# AT90PWM1 register map
Vendor: Atmel; File version: 1.0
CPU: other r0p0, little endian, no MPU, no FPU, 4 interrupt priority bits
Registers are 8-bit, read-write, reset 0x0 unless marked. A register's access mark holds for its fields unless they carry their own. Offsets are from the block's base; [hi:lo] are bit positions; {n}, {i} and the like mark numbered series; 'fields as' and 'values as' point back to an identical list.

## PSC2 — Power Stage Controller
Base 0x000000A4
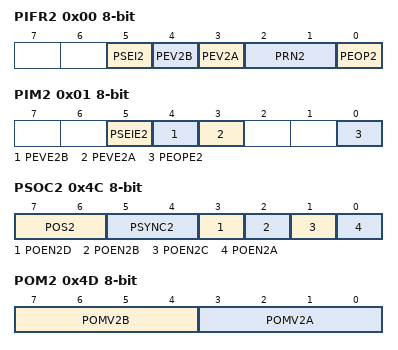
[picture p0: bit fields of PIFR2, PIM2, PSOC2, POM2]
0x00 PIFR2 — PSC2 Interrupt Flag Register
  [5] PSEI2 — PSC 2 Synchro Error Interrupt
  [4] PEV2B — External Event B Interrupt
  [3] PEV2A — External Event A Interrupt
  [2:1] PRN2 — Ramp Number
    {v}={v+1} (v=0..3)
  [0] PEOP2 — End of PSC2 Interrupt
0x01 PIM2 — PSC2 Interrupt Mask Register
  [5] PSEIE2 — PSC 2 Synchro Error Interrupt Enable
  [4] PEVE2B — External Event B Interrupt Enable
  [3] PEVE2A — External Event A Interrupt Enable
  [0] PEOPE2 — End of Cycle Interrupt Enable
0x4C PSOC2 — PSC2 Synchro and Output Configuration
  [7:6] POS2 — PSC 2 Output 23 Select
  [5:4] PSYNC2 — Synchronization Out for ADC Selection
  [3] POEN2D — PSCOUT23 Output Enable
  [2] POEN2B — PSCOUT21 Output Enable
  [1] POEN2C — PSCOUT22 Output Enable
  [0] POEN2A — PSCOUT20 Output Enable
0x4D POM2 — PSC 2 Output Matrix
  [7:4] POMV2B — Output Matrix Output B Ramps
  [3:0] POMV2A — Output Matrix Output A Ramps
0x4E OCR2SA 16-bit (reset mask 0xFF) — Output Compare SA Register
0x50 OCR2RA 16-bit (reset mask 0xFF) — Output Compare RA Register
0x52 OCR2SB 16-bit (reset mask 0xFF) — Output Compare SB Register
0x54 OCR2RB 16-bit (reset mask 0xFF) — Output Compare RB Register
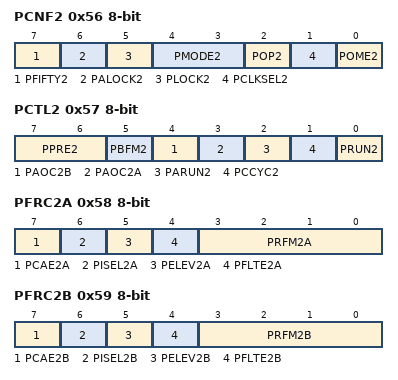
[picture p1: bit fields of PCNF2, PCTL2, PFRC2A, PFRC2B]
0x56 PCNF2 — PSC 2 Configuration Register
  [7] PFIFTY2 — PSC 2 Fifty
  [6] PALOCK2 — PSC 2 Autolock
  [5] PLOCK2 — PSC 2 Lock
  [4:3] PMODE2 — PSC 2 Mode
    0=One Ramp Mode; 1=Two Ramp Mode; 2=Four Ramp Mode; 3=Center Aligned Mode
  [2] POP2 — PSC 2 Output Polarity
  [1] PCLKSEL2 — PSC 2 Input Clock Select
  [0] POME2 — PSC 2 Output Matrix Enable
0x57 PCTL2 — PSC 2 Control Register
  [7:6] PPRE2 — PSC 2 Prescaler Selects
    0=No divider on PSC input clock; 1=Divide the PSC input clock by 4; 2=Divide the PSC input clock by 16; 3=Divide the PSC input clock by 64
  [5] PBFM2 — Balance Flank Width Modulation
  [4] PAOC2B — PSC 2 Asynchronous Output Control B
  [3] PAOC2A — PSC 2 Asynchronous Output Control A
  [2] PARUN2 — PSC2 Auto Run
  [1] PCCYC2 — PSC2 Complete Cycle
  [0] PRUN2 — PSC 2 Run
0x58 PFRC2A — PSC 2 Input B Control
  [7] PCAE2A — PSC 2 Capture Enable Input Part A
  [6] PISEL2A — PSC 2 Input Select for Part A
  [5] PELEV2A — PSC 2 Edge Level Selector on Input Part A
  [4] PFLTE2A — PSC 2 Filter Enable on Input Part A
  [3:0] PRFM2A — PSC 2 Retrigger and Fault Mode for Part A
    0=No action, PSC Input is ignored; 1=Stop signal, Jump to Opposite Dead-Time and Wait; 2=Stop signal, Execute Opposite Dead-Time and Wait; 3=Stop signal, Execute Opposite while Fault active; 4=Deactivate outputs without changing timing; 5=Stop signal and Insert Dead-Time; 6=Stop signal, Jump to Opposite Dead-Time and Wait; 7=Halt PSC and Wait for Software Action; 8=Edge Retrigger PSC; 9=Fixed Frequency Edge Retrigger PSC; 14=Fixed Frequency Edge Retrigger PSC and Disactivate Output
0x59 PFRC2B — PSC 2 Input B Control
  [7] PCAE2B — PSC 2 Capture Enable Input Part B
  [6] PISEL2B — PSC 2 Input Select for Part B
  [5] PELEV2B — PSC 2 Edge Level Selector on Input Part B
  [4] PFLTE2B — PSC 2 Filter Enable on Input Part B
  [3:0] PRFM2B — PSC 2 Retrigger and Fault Mode for Part B
    values as PFRC2A.PRFM2A
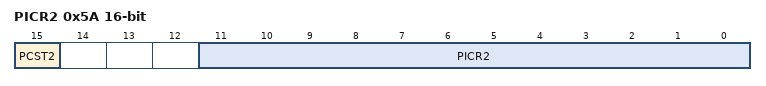
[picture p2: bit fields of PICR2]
0x5A PICR2 16-bit (reset mask 0xFF) — PSC 2 Input Capture Register
  [15] PCST2 — PSC 2 Capture Software Trig bit
  [11:0] PICR2 — PSC 2 Input Capture Register

## SPI — Serial Peripheral Interface
Base 0x0000004C
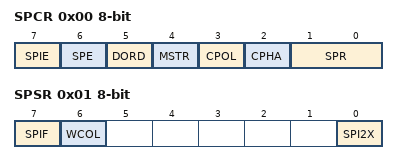
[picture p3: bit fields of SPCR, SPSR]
0x00 SPCR — SPI Control Register
  [7] SPIE — SPI Interrupt Enable
  [6] SPE — SPI Enable
  [5] DORD — Data Order
  [4] MSTR — Master/Slave Select
  [3] CPOL — Clock polarity
  [2] CPHA — Clock Phase
  [1:0] SPR — SPI Clock Rate Selects
    0=fosc/4; 1=fosc/16; 2=fosc/64; 3=fosc/128
0x01 SPSR — SPI Status Register
  [7] SPIF — SPI Interrupt Flag
  [6] WCOL — Write Collision Flag
  [0] SPI2X — Double SPI Speed Bit
0x02 SPDR — SPI Data Register
  [7:0] SPD — SPI Data
